# MKW41Z4 register map
Vendor: Freescale Semiconductor, Inc.; Series: Kinetis_W; File version: 1.6
CPU: CM0PLUS r0p0, little endian, no MPU, no FPU, VTOR, 2 interrupt priority bits
Registers are 16-bit, read-write, no defined reset value unless marked. A register's access mark holds for its fields unless they carry their own. Offsets are from the block's base; [hi:lo] are bit positions; {n}, {i} and the like mark numbered series; 'fields as' and 'values as' point back to an identical list.

## TRNG0
Base 0x40029000
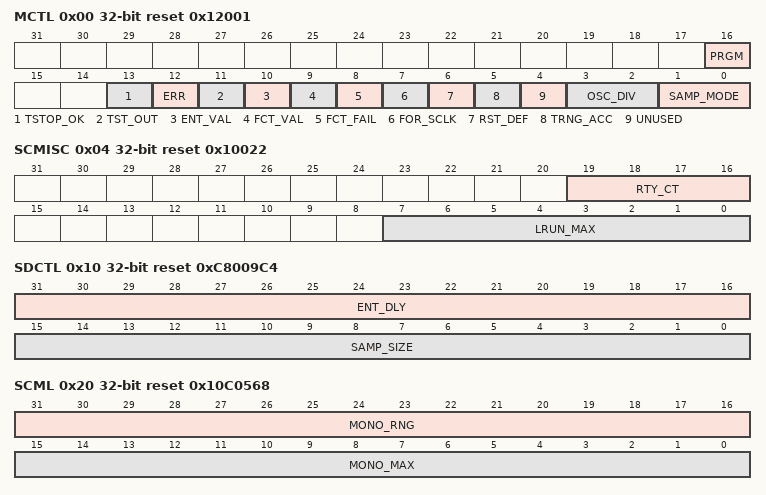
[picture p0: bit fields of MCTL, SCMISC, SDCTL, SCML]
0x00 MCTL 32-bit reset 0x12001 — Miscellaneous Control Register
  [16] PRGM — Programming Mode Select
  [13] TSTOP_OK ro — TRNG_OK_TO_STOP
  [12] ERR — Read: Error status
  [11] TST_OUT ro — Read only: Test point inside ring oscillator.
  [10] ENT_VAL ro — Read only: Entropy Valid
  [9] FCT_VAL ro — Read only: Frequency Count Valid. Indicates that a valid frequency count may be read from FRQCNT.
  [8] FCT_FAIL ro — Read only: Frequency Count Fail
  [7] FOR_SCLK — Force System Clock
  [6] RST_DEF wo — Reset Defaults
  [5] TRNG_ACC — TRNG Access Mode
  [4] UNUSED — This bit is unused but write-able. Must be left as zero.
  [3:2] OSC_DIV — Oscillator Divide
    0=use ring oscillator with no divide; 1=use ring oscillator divided-by-2; 2=use ring oscillator divided-by-4; 3=use ring oscillator divided-by-8
  [1:0] SAMP_MODE — Sample Mode
    0=use Von Neumann data into both Entropy shifter and Statistical Checker; 1=use raw data into both Entropy shifter and Statistical Checker; 2=use Von Neumann data into Entropy shifter. Use raw data into Statistical Checker; 3=undefined/reserved
0x04 SCMISC 32-bit reset 0x10022 — Statistical Check Miscellaneous Register
  [19:16] RTY_CT — RETRY COUNT
  [7:0] LRUN_MAX — LONG RUN MAX LIMIT
0x08 PKRRNG 32-bit reset 0x9A3 — Poker Range Register
  [15:0] PKR_RNG — Poker Range
0x0C PKRMAX 32-bit reset 0x6920 (TRNG0 view) — Poker Maximum Limit Register
  [23:0] PKR_MAX — Poker Maximum Limit.
0x0C PKRSQ 32-bit ro reset 0x0 (TRNG0 view) — Poker Square Calculation Result Register
  [23:0] PKR_SQ — Poker Square Calculation Result.
0x10 SDCTL 32-bit reset 0xC8009C4 — Seed Control Register
  [31:16] ENT_DLY — Entropy Delay
  [15:0] SAMP_SIZE — Sample Size
0x14 SBLIM 32-bit reset 0x3F (TRNG0 view) — Sparse Bit Limit Register
  [9:0] SB_LIM — Sparse Bit Limit
0x14 TOTSAM 32-bit ro reset 0x0 (TRNG0 view) — Total Samples Register
  [19:0] TOT_SAM — Total Samples
0x18 FRQMIN 32-bit reset 0x640 — Frequency Count Minimum Limit Register
  [21:0] FRQ_MIN — Frequency Count Minimum Limit
0x1C FRQCNT 32-bit ro reset 0x0 (TRNG0 view) — Frequency Count Register
  [21:0] FRQ_CT — Frequency Count
0x1C FRQMAX 32-bit reset 0x6400 (TRNG0 view) — Frequency Count Maximum Limit Register
  [21:0] FRQ_MAX — Frequency Counter Maximum Limit
0x20 SCMC 32-bit ro reset 0x0 (TRNG0 view) — Statistical Check Monobit Count Register
  [15:0] MONO_CT — Monobit Count
0x20 SCML 32-bit reset 0x10C0568 (TRNG0 view) — Statistical Check Monobit Limit Register
  [31:16] MONO_RNG — Monobit Range
  [15:0] MONO_MAX — Monobit Maximum Limit
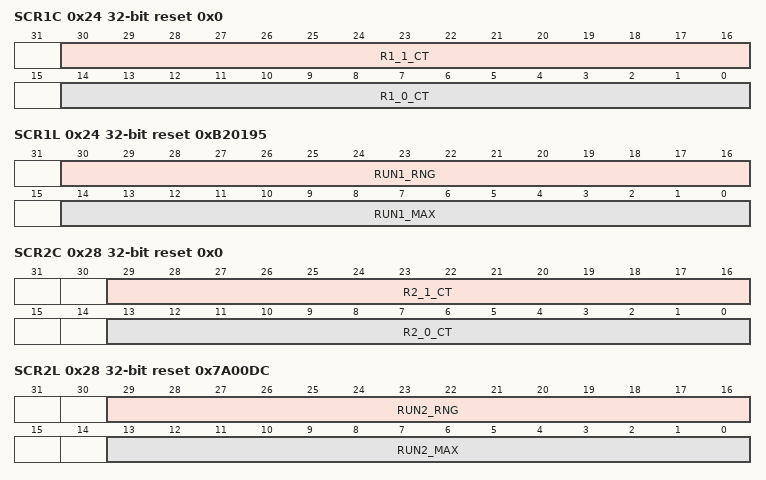
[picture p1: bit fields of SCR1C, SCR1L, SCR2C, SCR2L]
0x24 SCR1C 32-bit ro reset 0x0 (TRNG0 view) — Statistical Check Run Length 1 Count Register
  [30:16] R1_1_CT — Runs of One, Length 1 Count
  [14:0] R1_0_CT — Runs of Zero, Length 1 Count
0x24 SCR1L 32-bit reset 0xB20195 (TRNG0 view) — Statistical Check Run Length 1 Limit Register
  [30:16] RUN1_RNG — Run Length 1 Range
  [14:0] RUN1_MAX — Run Length 1 Maximum Limit
0x28 SCR2C 32-bit ro reset 0x0 (TRNG0 view) — Statistical Check Run Length 2 Count Register
  [29:16] R2_1_CT — Runs of One, Length 2 Count
  [13:0] R2_0_CT — Runs of Zero, Length 2 Count
0x28 SCR2L 32-bit reset 0x7A00DC (TRNG0 view) — Statistical Check Run Length 2 Limit Register
  [29:16] RUN2_RNG — Run Length 2 Range
  [13:0] RUN2_MAX — Run Length 2 Maximum Limit
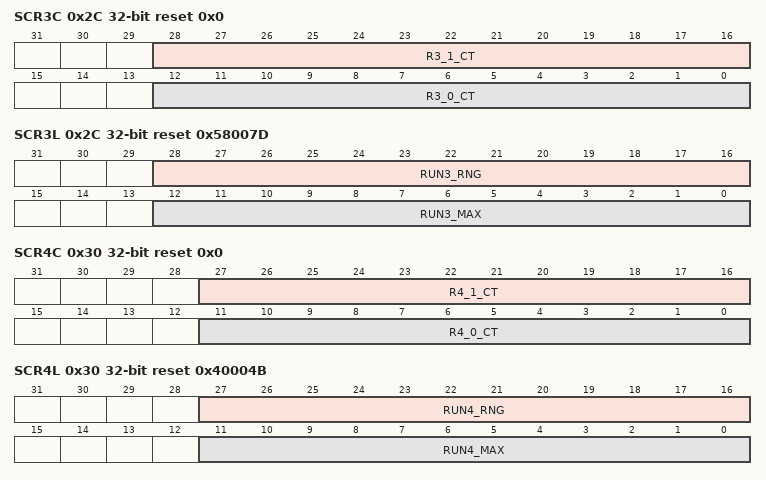
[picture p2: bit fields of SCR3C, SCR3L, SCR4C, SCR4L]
0x2C SCR3C 32-bit ro reset 0x0 (TRNG0 view) — Statistical Check Run Length 3 Count Register
  [28:16] R3_1_CT — Runs of Ones, Length 3 Count
  [12:0] R3_0_CT — Runs of Zeroes, Length 3 Count
0x2C SCR3L 32-bit reset 0x58007D (TRNG0 view) — Statistical Check Run Length 3 Limit Register
  [28:16] RUN3_RNG — Run Length 3 Range
  [12:0] RUN3_MAX — Run Length 3 Maximum Limit
0x30 SCR4C 32-bit ro reset 0x0 (TRNG0 view) — Statistical Check Run Length 4 Count Register
  [27:16] R4_1_CT — Runs of One, Length 4 Count
  [11:0] R4_0_CT — Runs of Zero, Length 4 Count
0x30 SCR4L 32-bit reset 0x40004B (TRNG0 view) — Statistical Check Run Length 4 Limit Register
  [27:16] RUN4_RNG — Run Length 4 Range
  [11:0] RUN4_MAX — Run Length 4 Maximum Limit
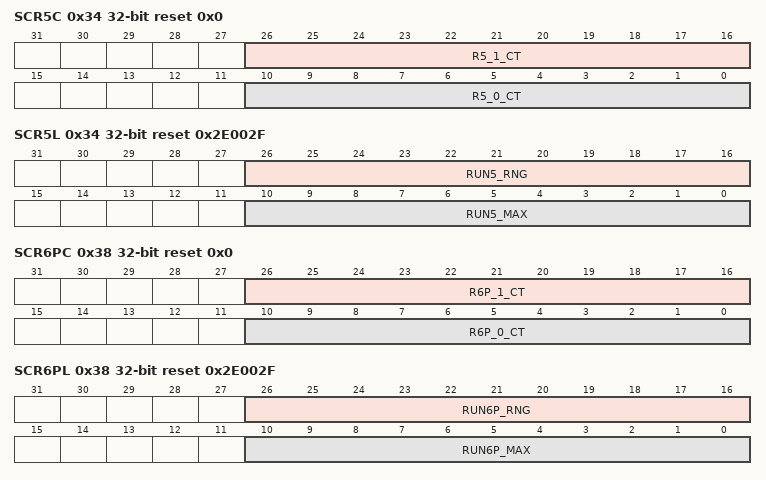
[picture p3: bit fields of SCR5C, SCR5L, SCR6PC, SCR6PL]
0x34 SCR5C 32-bit ro reset 0x0 (TRNG0 view) — Statistical Check Run Length 5 Count Register
  [26:16] R5_1_CT — Runs of One, Length 5 Count
  [10:0] R5_0_CT — Runs of Zero, Length 5 Count
0x34 SCR5L 32-bit reset 0x2E002F (TRNG0 view) — Statistical Check Run Length 5 Limit Register
  [26:16] RUN5_RNG — Run Length 5 Range
  [10:0] RUN5_MAX — Run Length 5 Maximum Limit
0x38 SCR6PC 32-bit ro reset 0x0 (TRNG0 view) — Statistical Check Run Length 6+ Count Register
  [26:16] R6P_1_CT — Runs of One, Length 6+ Count
  [10:0] R6P_0_CT — Runs of Zero, Length 6+ Count
0x38 SCR6PL 32-bit reset 0x2E002F (TRNG0 view) — Statistical Check Run Length 6+ Limit Register
  [26:16] RUN6P_RNG — Run Length 6+ Range
  [10:0] RUN6P_MAX — Run Length 6+ Maximum Limit
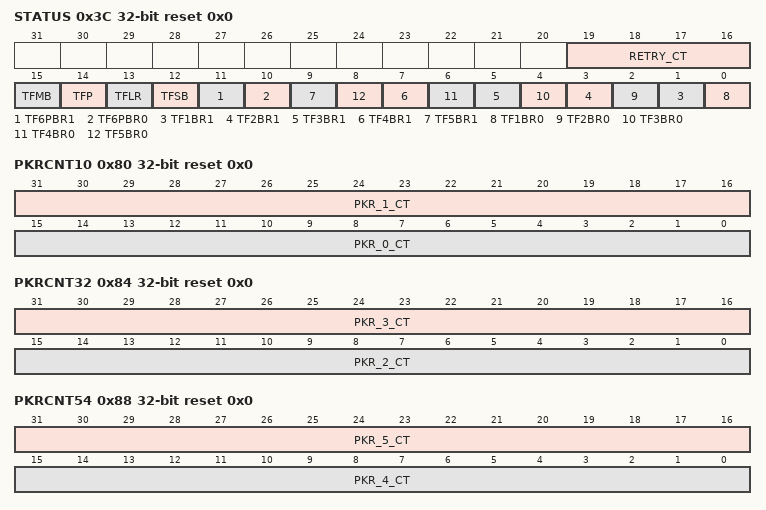
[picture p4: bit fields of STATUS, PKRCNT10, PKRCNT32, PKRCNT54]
0x3C STATUS 32-bit ro reset 0x0
  [19:16] RETRY_CT — RETRY COUNT
  [15] TFMB — Test Fail, Mono Bit. If TFMB=1, the Mono Bit Test has failed.
  [14] TFP — Test Fail, Poker. If TFP=1, the Poker Test has failed.
  [13] TFLR — Test Fail, Long Run. If TFLR=1, the Long Run Test has failed.
  [12] TFSB — Test Fail, Sparse Bit. If TFSB=1, the Sparse Bit Test has failed.
  [11] TF6PBR1 — Test Fail, 6 Plus Bit Run, Sampling 1s
  [10] TF6PBR0 — Test Fail, 6 Plus Bit Run, Sampling 0s
  [2n-1] TF{n}BR1 (n=1..5) — Test Fail, {n}-Bit Run, Sampling 1s. If TF{n}BR1=1, the {n}-Bit Run, Sampling 1s Test has failed.
  [2n-2] TF{n}BR0 (n=1..5) — Test Fail, {n}-Bit Run, Sampling 0s. If TF{n}BR0=1, the {n}-Bit Run, Sampling 0s Test has failed.
{0x40+4i} ENT{i} 32-bit ro reset 0x0 (i=0..15) — Entropy Read Register
  [31:0] ENT — Entropy Value
0x80 PKRCNT10 32-bit ro reset 0x0 — Statistical Check Poker Count 1 and 0 Register
  [31:16] PKR_1_CT — Poker 1h Count
  [15:0] PKR_0_CT — Poker 0h Count
0x84 PKRCNT32 32-bit ro reset 0x0 — Statistical Check Poker Count 3 and 2 Register
  [31:16] PKR_3_CT — Poker 3h Count
  [15:0] PKR_2_CT — Poker 2h Count
0x88 PKRCNT54 32-bit ro reset 0x0 — Statistical Check Poker Count 5 and 4 Register
  [31:16] PKR_5_CT — Poker 5h Count
  [15:0] PKR_4_CT — Poker 4h Count
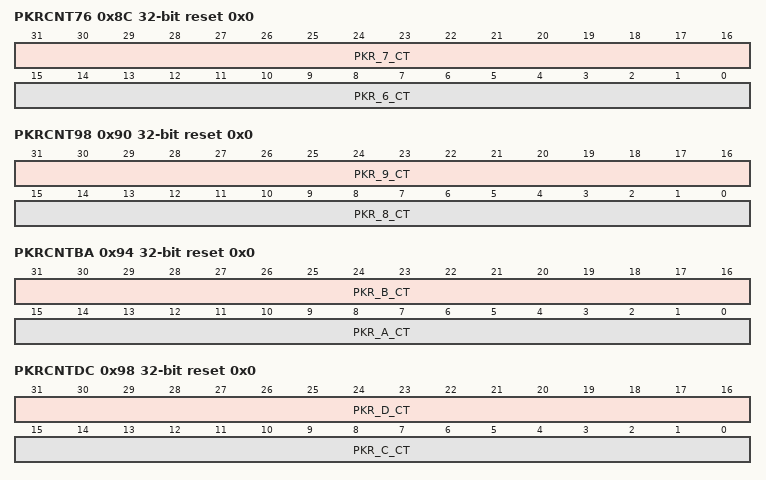
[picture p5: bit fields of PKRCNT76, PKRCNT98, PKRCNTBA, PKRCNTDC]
0x8C PKRCNT76 32-bit ro reset 0x0 — Statistical Check Poker Count 7 and 6 Register
  [31:16] PKR_7_CT — Poker 7h Count
  [15:0] PKR_6_CT — Poker 6h Count
0x90 PKRCNT98 32-bit ro reset 0x0 — Statistical Check Poker Count 9 and 8 Register
  [31:16] PKR_9_CT — Poker 9h Count
  [15:0] PKR_8_CT — Poker 8h Count
0x94 PKRCNTBA 32-bit ro reset 0x0 — Statistical Check Poker Count B and A Register
  [31:16] PKR_B_CT — Poker Bh Count
  [15:0] PKR_A_CT — Poker Ah Count
0x98 PKRCNTDC 32-bit ro reset 0x0 — Statistical Check Poker Count D and C Register
  [31:16] PKR_D_CT — Poker Dh Count
  [15:0] PKR_C_CT — Poker Ch Count
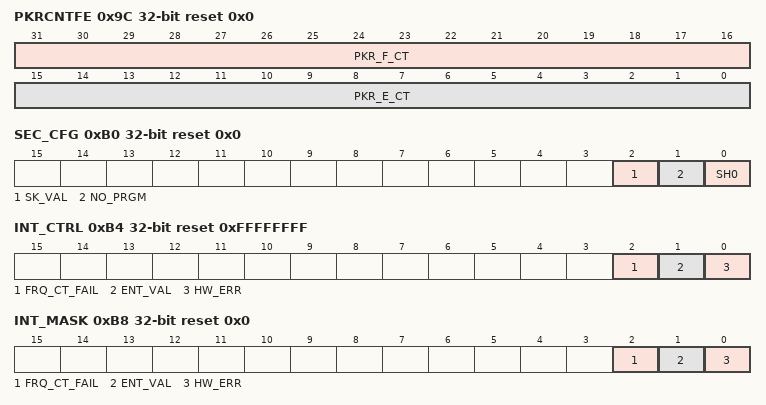
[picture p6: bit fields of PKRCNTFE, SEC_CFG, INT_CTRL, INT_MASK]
0x9C PKRCNTFE 32-bit ro reset 0x0 — Statistical Check Poker Count F and E Register
  [31:16] PKR_F_CT — Poker Fh Count
  [15:0] PKR_E_CT — Poker Eh Count
0xB0 SEC_CFG 32-bit reset 0x0 — Security Configuration Register
  [2] SK_VAL — Reserved. DRNG-specific, not applicable to this version.
    0=See DRNG version; 1=See DRNG version
  [1] NO_PRGM — If set, the TRNG registers cannot be programmed
    0=Programability of registers controlled only by the Miscellaneous Control Register's access mode bit; 1=Overides Miscellaneous Control Register access mode and prevents TRNG register programming
  [0] SH0 — Reserved. DRNG specific, not applicable to this version.
    0=See DRNG version; 1=See DRNG version
0xB4 INT_CTRL 32-bit reset 0xFFFFFFFF — Interrupt Control Register
  [2] FRQ_CT_FAIL — Same behavior as bit 0 above.
    0=Same behavior as bit 0 above; 1=Same behavior as bit 0 above
  [1] ENT_VAL — Same behavior as bit 0 above.
    values as FRQ_CT_FAIL
  [0] HW_ERR — Bit position that can be cleared if corresponding bit of INT_STATUS has been asserted.
    0=Corresponding bit of INT_STATUS cleared; 1=Corresponding bit of INT_STATUS active
0xB8 INT_MASK 32-bit reset 0x0 — Mask Register
  [2] FRQ_CT_FAIL — Same behavior as bit 0 above.
    values as INT_CTRL.FRQ_CT_FAIL
  [1] ENT_VAL — Same behavior as bit 0 above.
    values as INT_CTRL.FRQ_CT_FAIL
  [0] HW_ERR — Bit position that can be cleared if corresponding bit of INT_STATUS has been asserted.
    0=Corresponding interrupt of INT_STATUS is masked; 1=Corresponding bit of INT_STATUS is active
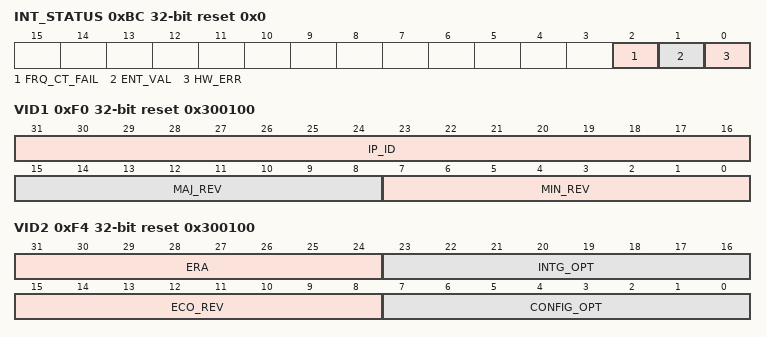
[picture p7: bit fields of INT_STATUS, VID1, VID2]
0xBC INT_STATUS 32-bit reset 0x0 — Interrupt Status Register
  [2] FRQ_CT_FAIL — Read only: Frequency Count Fail
    0=No hardware nor self test frequency errors; 1=The frequency counter has detected a failure
  [1] ENT_VAL ro — Read only: Entropy Valid
    0=Busy generation entropy. Any value read is invalid.; 1=TRNG can be stopped and entropy is valid if read
  [0] HW_ERR ro — Read: Error status
    0=no error; 1=error detected
0xF0 VID1 32-bit ro reset 0x300100 — Version ID Register (MS)
  [31:16] IP_ID — Shows the Freescale IP ID.
    48=ID for TRNG
  [15:8] MAJ_REV — Shows the Freescale IP's Major revision of the TRNG.
    1=Major revision number for TRNG
  [7:0] MIN_REV — Shows the Freescale IP's Minor revision of the TRNG.
    0=Minor revision number for TRNG
0xF4 VID2 32-bit ro reset 0x300100 — Version ID Register (LS)
  [31:24] ERA — Shows the Freescale compile options for the TRNG.
    0=COMPILE_OPT for TRNG
  [23:16] INTG_OPT — Shows the Freescale integration options for the TRNG.
    0=INTG_OPT for TRNG
  [15:8] ECO_REV — Shows the Freescale IP's ECO revision of the TRNG.
    0=TRNG_ECO_REV for TRNG
  [7:0] CONFIG_OPT — Shows the Freescale IP's Configuaration options for the TRNG.
    0=TRNG_CONFIG_OPT for TRNG
